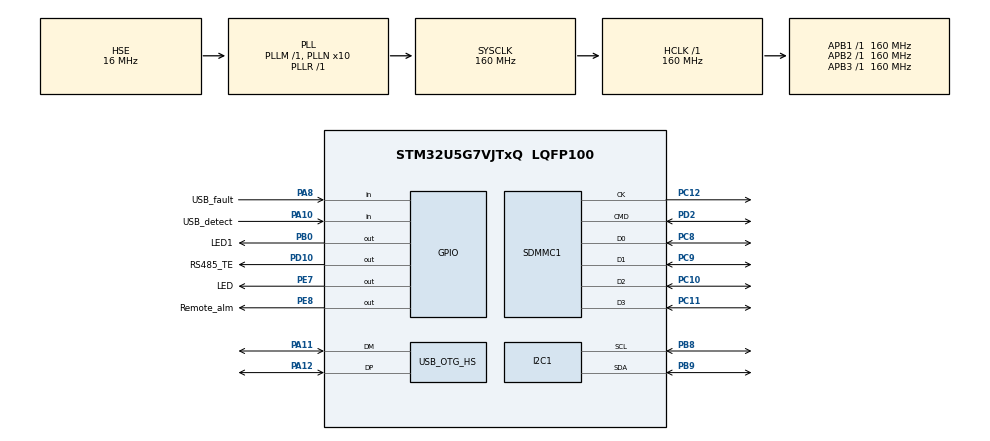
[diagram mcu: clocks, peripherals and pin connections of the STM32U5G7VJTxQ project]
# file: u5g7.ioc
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CORTEX_M33_NS.userName=CORTEX_M33
FILEX.FILEX_APPLICATION_THREAD_STACK_SIZE=1024*4
FILEX.FX_APP_MEM_POOL_SIZE=1024*8
FILEX.FX_MMC_INTERFACE=1
FILEX.useRTOS=1
I2C1.I2C_Rise_Time=100
I2C1.Timing=0x30D09DE8
Mcu.Family=STM32U5
Mcu.Name=STM32U5G7VJTxQ
Mcu.Package=LQFP100
NVIC.I2C1_ER_IRQn=true\:0\:0\:false\:false\:true\:false\:true\:true\:true
NVIC.I2C1_EV_IRQn=true\:0\:0\:false\:false\:true\:false\:true\:true\:true
NVIC.OTG_HS_IRQn=true\:0\:0\:false\:false\:true\:false\:true\:true\:true
NVIC.PriorityGroup=NVIC_PRIORITYGROUP_4
NVIC.SDMMC1_IRQn=true\:0\:0\:false\:false\:true\:false\:true\:true\:true
NVIC.TIM6_IRQn=true\:15\:0\:false\:false\:true\:false\:false\:true\:true
NVIC.TIM7_IRQn=true\:0\:0\:false\:false\:true\:false\:true\:true\:true
NVIC.TimeBase=TIM6_IRQn
NVIC.TimeBaseIP=TIM6
PA10.GPIO_Label=USB_detect
PA10.Signal=GPIO_Input
PA11.Mode=Internal_Phy_Device
PA11.Signal=USB_OTG_HS_DM
PA12.Mode=Internal_Phy_Device
PA12.Signal=USB_OTG_HS_DP
PA8.GPIO_Label=USB_fault
PA8.Signal=GPIO_Input
PB0.GPIO_Label=LED1
PB0.Signal=GPIO_Output
PB8.GPIO_Pu=GPIO_PULLUP
PB8.GPIO_Speed=GPIO_SPEED_FREQ_VERY_HIGH
PB8.Mode=I2C
PB8.Signal=I2C1_SCL
PB9.GPIO_Pu=GPIO_PULLUP
PB9.GPIO_Speed=GPIO_SPEED_FREQ_VERY_HIGH
PB9.Mode=I2C
PB9.Signal=I2C1_SDA
PC10.Mode=mmc_4_bits_Wide_bus
PC10.Signal=SDMMC1_D2
PC11.Mode=mmc_4_bits_Wide_bus
PC11.Signal=SDMMC1_D3
PC12.Mode=mmc_4_bits_Wide_bus
PC12.Signal=SDMMC1_CK
PC14-OSC32_IN\ (PC14).Mode=LSE-External-Oscillator
PC14-OSC32_IN\ (PC14).Signal=RCC_OSC32_IN
PC15-OSC32_OUT\ (PC15).Mode=LSE-External-Oscillator
PC15-OSC32_OUT\ (PC15).Signal=RCC_OSC32_OUT
PC8.Mode=mmc_4_bits_Wide_bus
PC8.Signal=SDMMC1_D0
PC9.Mode=mmc_4_bits_Wide_bus
PC9.Signal=SDMMC1_D1
PD10.GPIO_Label=RS485_TE
PD10.GPIO_PuPd=GPIO_PULLUP
PD10.GPIO_Speed=GPIO_SPEED_FREQ_HIGH
PD10.PinState=GPIO_PIN_SET
PD10.Signal=GPIO_Output
PD2.Mode=mmc_4_bits_Wide_bus
PD2.Signal=SDMMC1_CMD
PE7.GPIO_Label=LED
PE7.Signal=GPIO_Output
PE8.GPIO_Label=Remote_alm
PE8.GPIO_PuPd=GPIO_PULLUP
PE8.GPIO_Speed=GPIO_SPEED_FREQ_HIGH
PE8.PinState=GPIO_PIN_SET
PE8.Signal=GPIO_Output
PH0-OSC_IN\ (PH0).Mode=HSE-External-Oscillator
PH0-OSC_IN\ (PH0).Signal=RCC_OSC_IN
PH1-OSC_OUT\ (PH1).Mode=HSE-External-Oscillator
PH1-OSC_OUT\ (PH1).Signal=RCC_OSC_OUT
ProjectManager.HeapSize=0x200
ProjectManager.StackSize=0x400
ProjectManager.TargetToolchain=STM32CubeIDE
RCC.ADCFreq_Value=16000000
RCC.AHBFreq_Value=160000000
RCC.APB1Freq_Value=160000000
RCC.APB1TimFreq_Value=160000000
RCC.APB2Freq_Value=160000000
RCC.APB2TimFreq_Value=160000000
RCC.APB3Freq_Value=160000000
RCC.CortexFreq_Value=160000000
RCC.EPOD_VALUE=16000000
RCC.HCLKFreq_Value=160000000
RCC.HSE_VALUE=16000000
RCC.HSI48_VALUE=48000000
RCC.HSI_VALUE=16000000
RCC.LSIDIV_VALUE=32000
RCC.MSI_VALUE=4000000
RCC.PLL1R=1
RCC.PLLFRACN=0
RCC.PLLN=10
RCC.PLLSourceVirtual=RCC_PLLSOURCE_HSE
RCC.SYSCLKFreq_VALUE=160000000
RCC.SYSCLKSource=RCC_SYSCLKSOURCE_PLLCLK
RCC.USBPHYCLockSelection=RCC_USBPHYCLKSOURCE_HSE
RCC.VCOOutputFreq_Value=160000000
SDMMC1.ClockDiv=2
SDMMC1.ClockPowerSave=SDMMC_CLOCK_POWER_SAVE_ENABLE
SDMMC1.HardwareFlowControl=SDMMC_HARDWARE_FLOW_CONTROL_ENABLE
TIM7.PeriodNoDither=40000
TIM7.Prescaler=4
USBX.BSP.number=1
USBX.Core_System=1
USBX.MAX_POWER_IN_MILLI_AMPER=0
USBX.USBD_CDCACM_EPINCMD_ADDR=2
USBX.USBD_CDCACM_EPIN_ADDR=1
USBX.USBD_CDCACM_EPOUT_ADDR=3
USBX.USBX_DEVICE_MEM_POOL_VAR_NAME=ux_device_app_byte_pool\\
USBX.USBX_DEVICE_SYS_SIZE=1024*4
USBX.UX_DEVICE_APP_MEM_POOL_SIZE=8192
USBX.UX_DEVICE_CDC_ACM=1
USBX.UX_Device_Controller=1
USBX.UX_Device_CoreStack=1
USBX.UX_SLAVE_REQUEST_DATA_MAX_LENGTH=512
USBX0.BSP.STBoard=false
USBX0.BSP.api=Unknown
USBX0.BSP.instance=USB_OTG_HS
USBX0.BSP.ip=USB_OTG_HS
USBX0.BSP.mode=Device_Only
USBX0.BSP.name=USBDevice
USBX0.BSP.solution=USB_OTG_HS
USB_OTG_HS.VirtualMode=Device_HS
VP_FILEX_VS_FileOoSystemJjFileXJjCore.Mode=FileX_Core
VP_FILEX_VS_MMCOointerface.Mode=MMC_interface
VP_ICACHE_VS_ICACHE.Mode=DirectMappedCache
VP_LPBAMQUEUE_VS_QUEUE.Mode=QUEUEMODE
VP_LPBAM_VS_SIG1.Mode=SmartRun
VP_LPBAM_VS_SIG4.Mode=LPDMA1
VP_MEMORYMAP_VS_MEMORYMAP.Mode=CurAppReg
VP_PWR_VS_SECSignals.Mode=Security/Privilege
VP_SYS_VS_tim6.Mode=TIM6
VP_THREADX_VS_RTOSJjThreadXJjCoreJjDefault.Mode=Core_Default
VP_TIM7_VS_ClockSourceINT.Mode=Enable_Timer
VP_USBX_Core_System.Mode=Core_System
VP_USBX_UX\ Device\ CDC\ ACM\ Class_HS.Mode=UX_Device_class_CDC_ACM_HS
VP_USBX_UX\ Device\ Controller_HS.Mode=UX_Device_Controller_HS
VP_USBX_UX\ Device\ CoreStack_HS.Mode=UX_Device_CoreStack_HS
board=custom

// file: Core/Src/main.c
/* USER CODE BEGIN Header */
/**
  ******************************************************************************
  * @file           : main.c
  * @brief          : Main program body
  ******************************************************************************
  * @attention
  *
  * Copyright (c) 2025 STMicroelectronics.
  * All rights reserved.
  *
  * This software is licensed under terms that can be found in the LICENSE file
  * in the root directory of this software component.
  * If no LICENSE file comes with this software, it is provided AS-IS.
  *
  ******************************************************************************
  */
/* USER CODE END Header */
#include "app_threadx.h"
#include "main.h"

/* USER CODE BEGIN Includes */
#include <mymain.h>
#include <FileX.h>
#include <BOOT.h>
/* USER CODE END Includes */

I2C_HandleTypeDef hi2c1;

MMC_HandleTypeDef hmmc1;

TIM_HandleTypeDef htim7;

PCD_HandleTypeDef hpcd_USB_OTG_HS;

void SystemClock_Config(void);
static void MX_GPIO_Init(void);
static void MX_SDMMC1_MMC_Init(void);
static void MX_TIM7_Init(void);
static void MX_ICACHE_Init(void);
static void MX_I2C1_Init(void);

int main(void)
{

  /* MCU Configuration--------------------------------------------------------*/

  /* Reset of all peripherals, Initializes the Flash interface and the Systick. */
  HAL_Init();

  /* Configure the system clock */
  SystemClock_Config();

  /* Initialize all configured peripherals */
  MX_GPIO_Init();
  MX_SDMMC1_MMC_Init();
  MX_TIM7_Init();
  MX_ICACHE_Init();
  MX_I2C1_Init();
  /* USER CODE BEGIN 2 */
  my_init();
  /* USER CODE END 2 */

  MX_ThreadX_Init();

  /* We should never get here as control is now taken by the scheduler */

  /* Infinite loop */
  while (1)
  {

  }
}

void SystemClock_Config(void)
{
  RCC_OscInitTypeDef RCC_OscInitStruct = {0};
  RCC_ClkInitTypeDef RCC_ClkInitStruct = {0};

  /** Configure the main internal regulator output voltage
  */
  if (HAL_PWREx_ControlVoltageScaling(PWR_REGULATOR_VOLTAGE_SCALE1) != HAL_OK)
  {
    Error_Handler();
  }

  /** Initializes the CPU, AHB and APB buses clocks
  */
  RCC_OscInitStruct.OscillatorType = RCC_OSCILLATORTYPE_HSE;
  RCC_OscInitStruct.HSEState = RCC_HSE_ON;
  RCC_OscInitStruct.PLL.PLLState = RCC_PLL_ON;
  RCC_OscInitStruct.PLL.PLLSource = RCC_PLLSOURCE_HSE;
  RCC_OscInitStruct.PLL.PLLMBOOST = RCC_PLLMBOOST_DIV1;
  RCC_OscInitStruct.PLL.PLLM = 1;
  RCC_OscInitStruct.PLL.PLLN = 10;
  RCC_OscInitStruct.PLL.PLLP = 2;
  RCC_OscInitStruct.PLL.PLLQ = 2;
  RCC_OscInitStruct.PLL.PLLR = 1;
  RCC_OscInitStruct.PLL.PLLRGE = RCC_PLLVCIRANGE_1;
  RCC_OscInitStruct.PLL.PLLFRACN = 0;
  if (HAL_RCC_OscConfig(&RCC_OscInitStruct) != HAL_OK)
  {
    Error_Handler();
  }

  /** Initializes the CPU, AHB and APB buses clocks
  */
  RCC_ClkInitStruct.ClockType = RCC_CLOCKTYPE_HCLK|RCC_CLOCKTYPE_SYSCLK
                              |RCC_CLOCKTYPE_PCLK1|RCC_CLOCKTYPE_PCLK2
                              |RCC_CLOCKTYPE_PCLK3;
  RCC_ClkInitStruct.SYSCLKSource = RCC_SYSCLKSOURCE_PLLCLK;
  RCC_ClkInitStruct.AHBCLKDivider = RCC_SYSCLK_DIV1;
  RCC_ClkInitStruct.APB1CLKDivider = RCC_HCLK_DIV1;
  RCC_ClkInitStruct.APB2CLKDivider = RCC_HCLK_DIV1;
  RCC_ClkInitStruct.APB3CLKDivider = RCC_HCLK_DIV1;

  if (HAL_RCC_ClockConfig(&RCC_ClkInitStruct, FLASH_LATENCY_4) != HAL_OK)
  {
    Error_Handler();
  }
}

static void MX_I2C1_Init(void)
{

  hi2c1.Instance = I2C1;
  hi2c1.Init.Timing = 0x30D09DE8;
  hi2c1.Init.OwnAddress1 = 0;
  hi2c1.Init.AddressingMode = I2C_ADDRESSINGMODE_7BIT;
  hi2c1.Init.DualAddressMode = I2C_DUALADDRESS_DISABLE;
  hi2c1.Init.OwnAddress2 = 0;
  hi2c1.Init.OwnAddress2Masks = I2C_OA2_NOMASK;
  hi2c1.Init.GeneralCallMode = I2C_GENERALCALL_DISABLE;
  hi2c1.Init.NoStretchMode = I2C_NOSTRETCH_DISABLE;
  if (HAL_I2C_Init(&hi2c1) != HAL_OK)
  {
    Error_Handler();
  }

  /** Configure Analogue filter
  */
  if (HAL_I2CEx_ConfigAnalogFilter(&hi2c1, I2C_ANALOGFILTER_ENABLE) != HAL_OK)
  {
    Error_Handler();
  }

  /** Configure Digital filter
  */
  if (HAL_I2CEx_ConfigDigitalFilter(&hi2c1, 0) != HAL_OK)
  {
    Error_Handler();
  }

}

static void MX_ICACHE_Init(void)
{

  /** Enable instruction cache in 1-way (direct mapped cache)
  */
  if (HAL_ICACHE_ConfigAssociativityMode(ICACHE_1WAY) != HAL_OK)
  {
    Error_Handler();
  }
  if (HAL_ICACHE_Enable() != HAL_OK)
  {
    Error_Handler();
  }

}

static void MX_SDMMC1_MMC_Init(void)
{

  hmmc1.Instance = SDMMC1;
  hmmc1.Init.ClockEdge = SDMMC_CLOCK_EDGE_RISING;
  hmmc1.Init.ClockPowerSave = SDMMC_CLOCK_POWER_SAVE_ENABLE;
  hmmc1.Init.BusWide = SDMMC_BUS_WIDE_4B;
  hmmc1.Init.HardwareFlowControl = SDMMC_HARDWARE_FLOW_CONTROL_ENABLE;
  hmmc1.Init.ClockDiv = 2;
  if (HAL_MMC_Init(&hmmc1) != HAL_OK)
  {
    Error_Handler();
  }

}

static void MX_TIM7_Init(void)
{

  TIM_MasterConfigTypeDef sMasterConfig = {0};

  htim7.Instance = TIM7;
  htim7.Init.Prescaler = 4;
  htim7.Init.CounterMode = TIM_COUNTERMODE_UP;
  htim7.Init.Period = 40000;
  htim7.Init.AutoReloadPreload = TIM_AUTORELOAD_PRELOAD_DISABLE;
  if (HAL_TIM_Base_Init(&htim7) != HAL_OK)
  {
    Error_Handler();
  }
  sMasterConfig.MasterOutputTrigger = TIM_TRGO_RESET;
  sMasterConfig.MasterSlaveMode = TIM_MASTERSLAVEMODE_DISABLE;
  if (HAL_TIMEx_MasterConfigSynchronization(&htim7, &sMasterConfig) != HAL_OK)
  {
    Error_Handler();
  }

}

void MX_USB_OTG_HS_PCD_Init(void)
{

  hpcd_USB_OTG_HS.Instance = USB_OTG_HS;
  hpcd_USB_OTG_HS.Init.dev_endpoints = 9;
  hpcd_USB_OTG_HS.Init.speed = PCD_SPEED_HIGH;
  hpcd_USB_OTG_HS.Init.phy_itface = USB_OTG_HS_EMBEDDED_PHY;
  hpcd_USB_OTG_HS.Init.Sof_enable = DISABLE;
  hpcd_USB_OTG_HS.Init.low_power_enable = DISABLE;
  hpcd_USB_OTG_HS.Init.lpm_enable = DISABLE;
  hpcd_USB_OTG_HS.Init.use_dedicated_ep1 = DISABLE;
  hpcd_USB_OTG_HS.Init.vbus_sensing_enable = DISABLE;
  hpcd_USB_OTG_HS.Init.dma_enable = DISABLE;
  if (HAL_PCD_Init(&hpcd_USB_OTG_HS) != HAL_OK)
  {
    Error_Handler();
  }

}

static void MX_GPIO_Init(void)
{
  GPIO_InitTypeDef GPIO_InitStruct = {0};

  /* GPIO Ports Clock Enable */
  __HAL_RCC_GPIOC_CLK_ENABLE();
  __HAL_RCC_GPIOH_CLK_ENABLE();
  __HAL_RCC_GPIOB_CLK_ENABLE();
  __HAL_RCC_GPIOE_CLK_ENABLE();
  __HAL_RCC_GPIOD_CLK_ENABLE();
  __HAL_RCC_GPIOA_CLK_ENABLE();

  /*Configure GPIO pin Output Level */
  HAL_GPIO_WritePin(LED1_GPIO_Port, LED1_Pin, GPIO_PIN_RESET);

  /*Configure GPIO pin Output Level */
  HAL_GPIO_WritePin(LED_GPIO_Port, LED_Pin, GPIO_PIN_RESET);

  /*Configure GPIO pin Output Level */
  HAL_GPIO_WritePin(Remote_alm_GPIO_Port, Remote_alm_Pin, GPIO_PIN_SET);

  /*Configure GPIO pin Output Level */
  HAL_GPIO_WritePin(RS485_TE_GPIO_Port, RS485_TE_Pin, GPIO_PIN_SET);

  /*Configure GPIO pin : LED1_Pin */
  GPIO_InitStruct.Pin = LED1_Pin;
  GPIO_InitStruct.Mode = GPIO_MODE_OUTPUT_PP;
  GPIO_InitStruct.Pull = GPIO_NOPULL;
  GPIO_InitStruct.Speed = GPIO_SPEED_FREQ_LOW;
  HAL_GPIO_Init(LED1_GPIO_Port, &GPIO_InitStruct);

  /*Configure GPIO pin : LED_Pin */
  GPIO_InitStruct.Pin = LED_Pin;
  GPIO_InitStruct.Mode = GPIO_MODE_OUTPUT_PP;
  GPIO_InitStruct.Pull = GPIO_NOPULL;
  GPIO_InitStruct.Speed = GPIO_SPEED_FREQ_LOW;
  HAL_GPIO_Init(LED_GPIO_Port, &GPIO_InitStruct);

  /*Configure GPIO pin : Remote_alm_Pin */
  GPIO_InitStruct.Pin = Remote_alm_Pin;
  GPIO_InitStruct.Mode = GPIO_MODE_OUTPUT_PP;
  GPIO_InitStruct.Pull = GPIO_PULLUP;
  GPIO_InitStruct.Speed = GPIO_SPEED_FREQ_HIGH;
  HAL_GPIO_Init(Remote_alm_GPIO_Port, &GPIO_InitStruct);

  /*Configure GPIO pin : RS485_TE_Pin */
  GPIO_InitStruct.Pin = RS485_TE_Pin;
  GPIO_InitStruct.Mode = GPIO_MODE_OUTPUT_PP;
  GPIO_InitStruct.Pull = GPIO_PULLUP;
  GPIO_InitStruct.Speed = GPIO_SPEED_FREQ_HIGH;
  HAL_GPIO_Init(RS485_TE_GPIO_Port, &GPIO_InitStruct);

  /*Configure GPIO pins : USB_fault_Pin USB_detect_Pin */
  GPIO_InitStruct.Pin = USB_fault_Pin|USB_detect_Pin;
  GPIO_InitStruct.Mode = GPIO_MODE_INPUT;
  GPIO_InitStruct.Pull = GPIO_NOPULL;
  HAL_GPIO_Init(GPIOA, &GPIO_InitStruct);

}

void HAL_TIM_PeriodElapsedCallback(TIM_HandleTypeDef *htim)
{
  if (htim->Instance == TIM6)
  {
    HAL_IncTick();
  }
}

void Error_Handler(void)
{
  __disable_irq();
  while (1)
  {
  }
}
